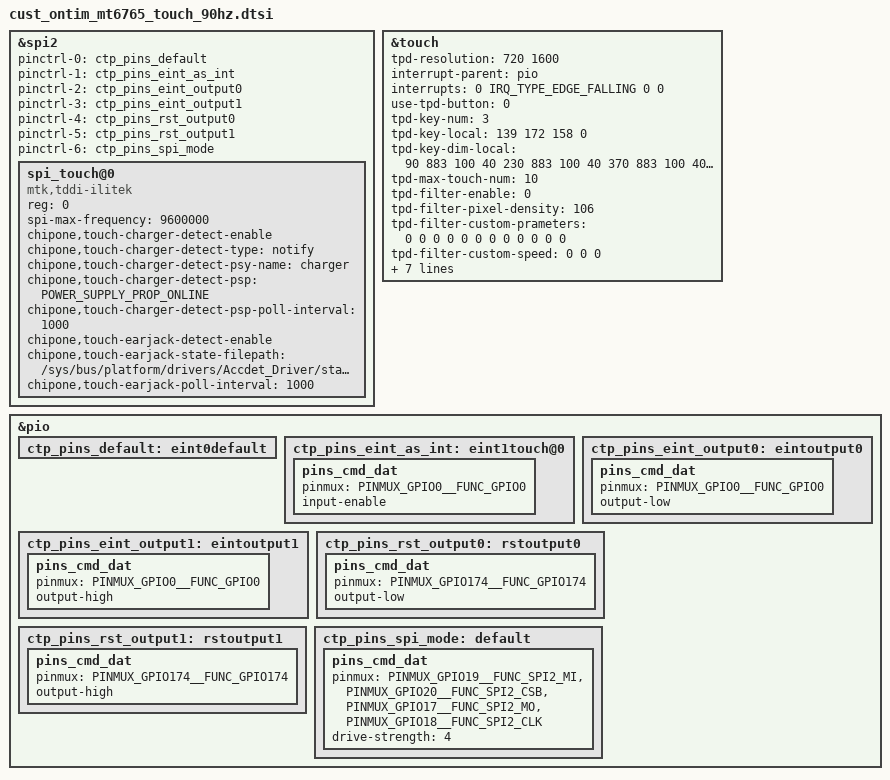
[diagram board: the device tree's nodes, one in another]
// SPDX-License-Identifier: GPL-2.0+
/*
 * Copyright (c) 2019 MediaTek Inc.
 *
*/



&spi2 {
	status = "okay";
	#address-cells = <1>;
	#size-cells = <0>;

	pinctrl-names = "default", "state_eint_as_int",
		"state_eint_output0", "state_eint_output1",
		"state_rst_output0", "state_rst_output1",
		"ctp_pins_spi_mode";
	pinctrl-0 = <&ctp_pins_default>;
	pinctrl-1 = <&ctp_pins_eint_as_int>;
	pinctrl-2 = <&ctp_pins_eint_output0>;
	pinctrl-3 = <&ctp_pins_eint_output1>;
	pinctrl-4 = <&ctp_pins_rst_output0>;
	pinctrl-5 = <&ctp_pins_rst_output1>;
	pinctrl-6 = <&ctp_pins_spi_mode>;

	spi_touch@0 {
		compatible = "mtk,tddi-ilitek", "chipone-tddi","focaltech,fts";
		reg = <0>;
		status = "okay";
		spi-max-frequency = <9600000>;
		/* Charger detect */
		chipone,touch-charger-detect-enable;
		chipone,touch-charger-detect-type = "notify"; /* notify, poll */
		chipone,touch-charger-detect-psy-name = "charger";
		chipone,touch-charger-detect-psp = "POWER_SUPPLY_PROP_ONLINE";
        	chipone,touch-charger-detect-psp-poll-interval = <1000>;

		/* Earjack detect */
		chipone,touch-earjack-detect-enable;
		/* MTK:  /sys/bus/platform/drivers/Accdet_Driver/state,
		Sprd: /sys/kernel/headset/state
		QCOM: None, and disable it */
		chipone,touch-earjack-state-filepath = "/sys/bus/platform/drivers/Accdet_Driver/state";
		chipone,touch-earjack-poll-interval = <1000>;
	};

};

&touch {
	tpd-resolution = <720 1600>;
	interrupt-parent = <&pio>;
	interrupts = <0 IRQ_TYPE_EDGE_FALLING 0 0>;
	use-tpd-button = <0>;
	tpd-key-num = <3>;
	tpd-key-local= <139 172 158 0>;
	tpd-key-dim-local = <90 883 100 40 230
				 883 100 40 370 883 100 40 0 0 0 0>;
	tpd-max-touch-num = <10>;
	tpd-filter-enable = <0>;
	tpd-filter-pixel-density = <106>;
	tpd-filter-custom-prameters = <0 0 0 0 0 0 0 0 0 0 0 0>;
	tpd-filter-custom-speed = <0 0 0>;
	pinctrl-names = "default", "state_eint_as_int",
		"state_eint_output0", "state_eint_output1",
		"state_rst_output0", "state_rst_output1";

	pinctrl-0 = <&ctp_pins_default>;
	pinctrl-1 = <&ctp_pins_eint_as_int>;
	pinctrl-2 = <&ctp_pins_eint_output0>;
	pinctrl-3 = <&ctp_pins_eint_output1>;
	pinctrl-4 = <&ctp_pins_rst_output0>;
	pinctrl-5 = <&ctp_pins_rst_output1>;
	pinctrl-6 = <&ctp_pins_spi_mode>;
	status = "okay";
};

&pio {
	ctp_pins_default: eint0default {
	};
	ctp_pins_eint_as_int: eint1touch@0 {
		pins_cmd_dat {
			pinmux = <PINMUX_GPIO0__FUNC_GPIO0>;
			input-enable;
		};
	};
	ctp_pins_eint_output0: eintoutput0 {
		pins_cmd_dat {
			pinmux = <PINMUX_GPIO0__FUNC_GPIO0>;
			output-low;
		};
	};
	ctp_pins_eint_output1: eintoutput1 {
		pins_cmd_dat {
			pinmux = <PINMUX_GPIO0__FUNC_GPIO0>;
			output-high;
		};
	};
	ctp_pins_rst_output0: rstoutput0 {
		pins_cmd_dat {
			pinmux = <PINMUX_GPIO174__FUNC_GPIO174>;
			output-low;
		};
	};
	ctp_pins_rst_output1: rstoutput1 {
		pins_cmd_dat {
			pinmux = <PINMUX_GPIO174__FUNC_GPIO174>;
			output-high;
		};
	};
	ctp_pins_spi_mode: default {
		pins_cmd_dat {
			pinmux = <PINMUX_GPIO19__FUNC_SPI2_MI>,
				<PINMUX_GPIO20__FUNC_SPI2_CSB>,
				<PINMUX_GPIO17__FUNC_SPI2_MO>,
				<PINMUX_GPIO18__FUNC_SPI2_CLK>;
			drive-strength = <4>;
		};
	};
};
/* TOUCH end */
